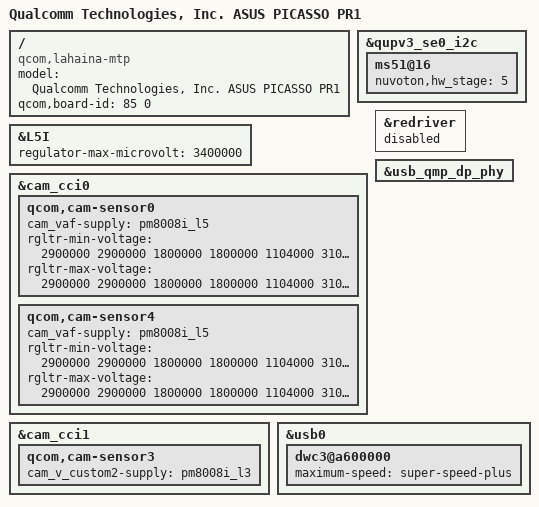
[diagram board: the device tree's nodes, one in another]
/dts-v1/;
/plugin/;

#include "PICASSO-ER2-overlay.dts"


/ {
	model = "Qualcomm Technologies, Inc. ASUS PICASSO PR1";
	compatible = "qcom,lahaina-mtp", "qcom,lahaina", "qcom,mtp";
	qcom,board-id = <85 0>;
};

/*   ====================================
*    overlay for display - start
*    ====================================
*/

/*   ====================================
*    overlay for display - end
*    ====================================
*/

/*    ====================================
 *    overlay for lahainap-v2.dtsi - start
 *    ====================================
 */

/*    ====================================
 *    overlay for lahainap-v2.dtsi - end
 *    ====================================
 */



/*    ====================================
 *    overlay for lahainap.dtsi - start
 *    ====================================
 */

/*    ====================================
 *    overlay for lahainap.dtsi - end
 *    ====================================
 */



/*    ====================================
 *    overlay for lahaina-mtp.dtsi - start
 *    ====================================
 */

&qupv3_se0_i2c {
	ms51@16 {
		nuvoton,hw_stage = <5>;
	};
};

/*    ====================================
 *    overlay for lahaina-mtp.dtsi - end
 *    ====================================
 */


/*    ====================================
 *    overlay for lahaina-pm.dtsi - start
 *    ====================================
 */

/*    ====================================
 *    overlay for lahaina-pm.dtsi - end
 *    ====================================
 */



/*    ====================================
 *    overlay for lahaina-pinctrl.dtsi - start
 *    ====================================
 */

/*    ====================================
 *    overlay for lahaina-pinctrl.dtsi - end
 *    ====================================
 */



/*    ====================================
 *    overlay for lahaina-pmic-overlay.dtsi - start
 *    ====================================
 */


&L5I {
	regulator-max-microvolt = <3400000>;
};

&cam_cci0 {
	qcom,cam-sensor0 {
		cam_vaf-supply = <&pm8008i_l5>; //<&cam_vm_3p1_en>;          //CAM0_VM_PWR_EN OR CAM0_VM_3P1: <&pm8008i_l5>
		rgltr-min-voltage = <2900000 2900000 1800000 1800000 1104000 3100000 0>;
		rgltr-max-voltage = <2900000 2900000 1800000 1800000 1104000 3100000 0>;
	};

	qcom,cam-sensor4 {
		cam_vaf-supply = <&pm8008i_l5>; //<&cam_vm_3p1_en>;          //CAM0_VM_PWR_EN OR CAM0_VM_3P1: <&pm8008i_l5>
		rgltr-min-voltage = <2900000 2900000 1800000 1800000 1104000 3100000 0>;
		rgltr-max-voltage = <2900000 2900000 1800000 1800000 1104000 3100000 0>;
	};
};

&cam_cci1 {
	qcom,cam-sensor3 {
		cam_v_custom2-supply = <&pm8008i_l3>;   //<&cam_8m_vm_2p8_en>;          //CAM2_VM_2P8 //PM8008_1_LDO3_2P8
	};
};

/*    ====================================
 *    overlay for lahaina-pmic-overlay.dtsi - end
 *    ====================================
 */


/*    ====================================
 *    overlay for pm8350.dtsi - start
 *    ====================================
 */

/*    ====================================
 *    overlay for pm8350.dtsi - end
 *    ====================================
 */


/*    ====================================
 *    overlay for pmk8350.dtsi - start
 *    ====================================
 */

/*    ====================================
 *    overlay for pmk8350.dtsi - end
 *    ====================================
 */

/*    ====================================
 *    overlay for pm8350b.dtsi - start
 *    ====================================
 */

/*    ====================================
 *    overlay for pm8350b.dtsi - end
 *    ====================================
 */

/*    ====================================
 *    overlay for pm8350c.dtsi - start
 *    ====================================
 */

/*    ====================================
 *    overlay for pm8350c.dtsi - end
 *    ====================================
 */


/*    ====================================
 *    overlay for lahaina-regulators.dtsi - start
 *    ====================================
 */

/*    ====================================
 *    overlay for lahaina-regulators.dtsi - end
 *    ====================================
 */
  

 
/*    ====================================
 *    overlay for lahaina-audio.dtsi - start
 *    ====================================
 */

/*    ====================================
 *    overlay for lahaina-audio.dtsi - end
 *    ====================================
 */

/*    ====================================
 *    overlay for lahaina-audio-overlay.dtsi - start
 *    ====================================
 */

/*    ====================================
 *    overlay for lahaina-audio-overlay.dtsi - end
 *    ====================================
 */


/*    ====================================
 *    overlay for lahaina-thermal-overlay.dtsi - start
 *    ====================================
 */

/*    ====================================
 *    overlay for lahaina-thermal-overlay.dtsi - end
 *    ====================================
 */

 
/*    ====================================
 *    overlay for lahaina-gpu.dtsi - start
 *    ====================================
 */

/*    ====================================
 *    overlay for lahaina-gpu.dtsi - end
 *    ====================================
 */


/*    ====================================
 *    overlay for lahaina-usb.dtsi - start
 *    ====================================
 */
&redriver {
	status = "disable";
};

&usb_qmp_dp_phy {
	pinctrl-names = "default";
};

&usb0 {
	dwc3@a600000 {
		maximum-speed = "super-speed-plus";
	};
};

/*    ====================================
 *    overlay for lahaina-usb.dtsi - end
 *    ====================================
 */
